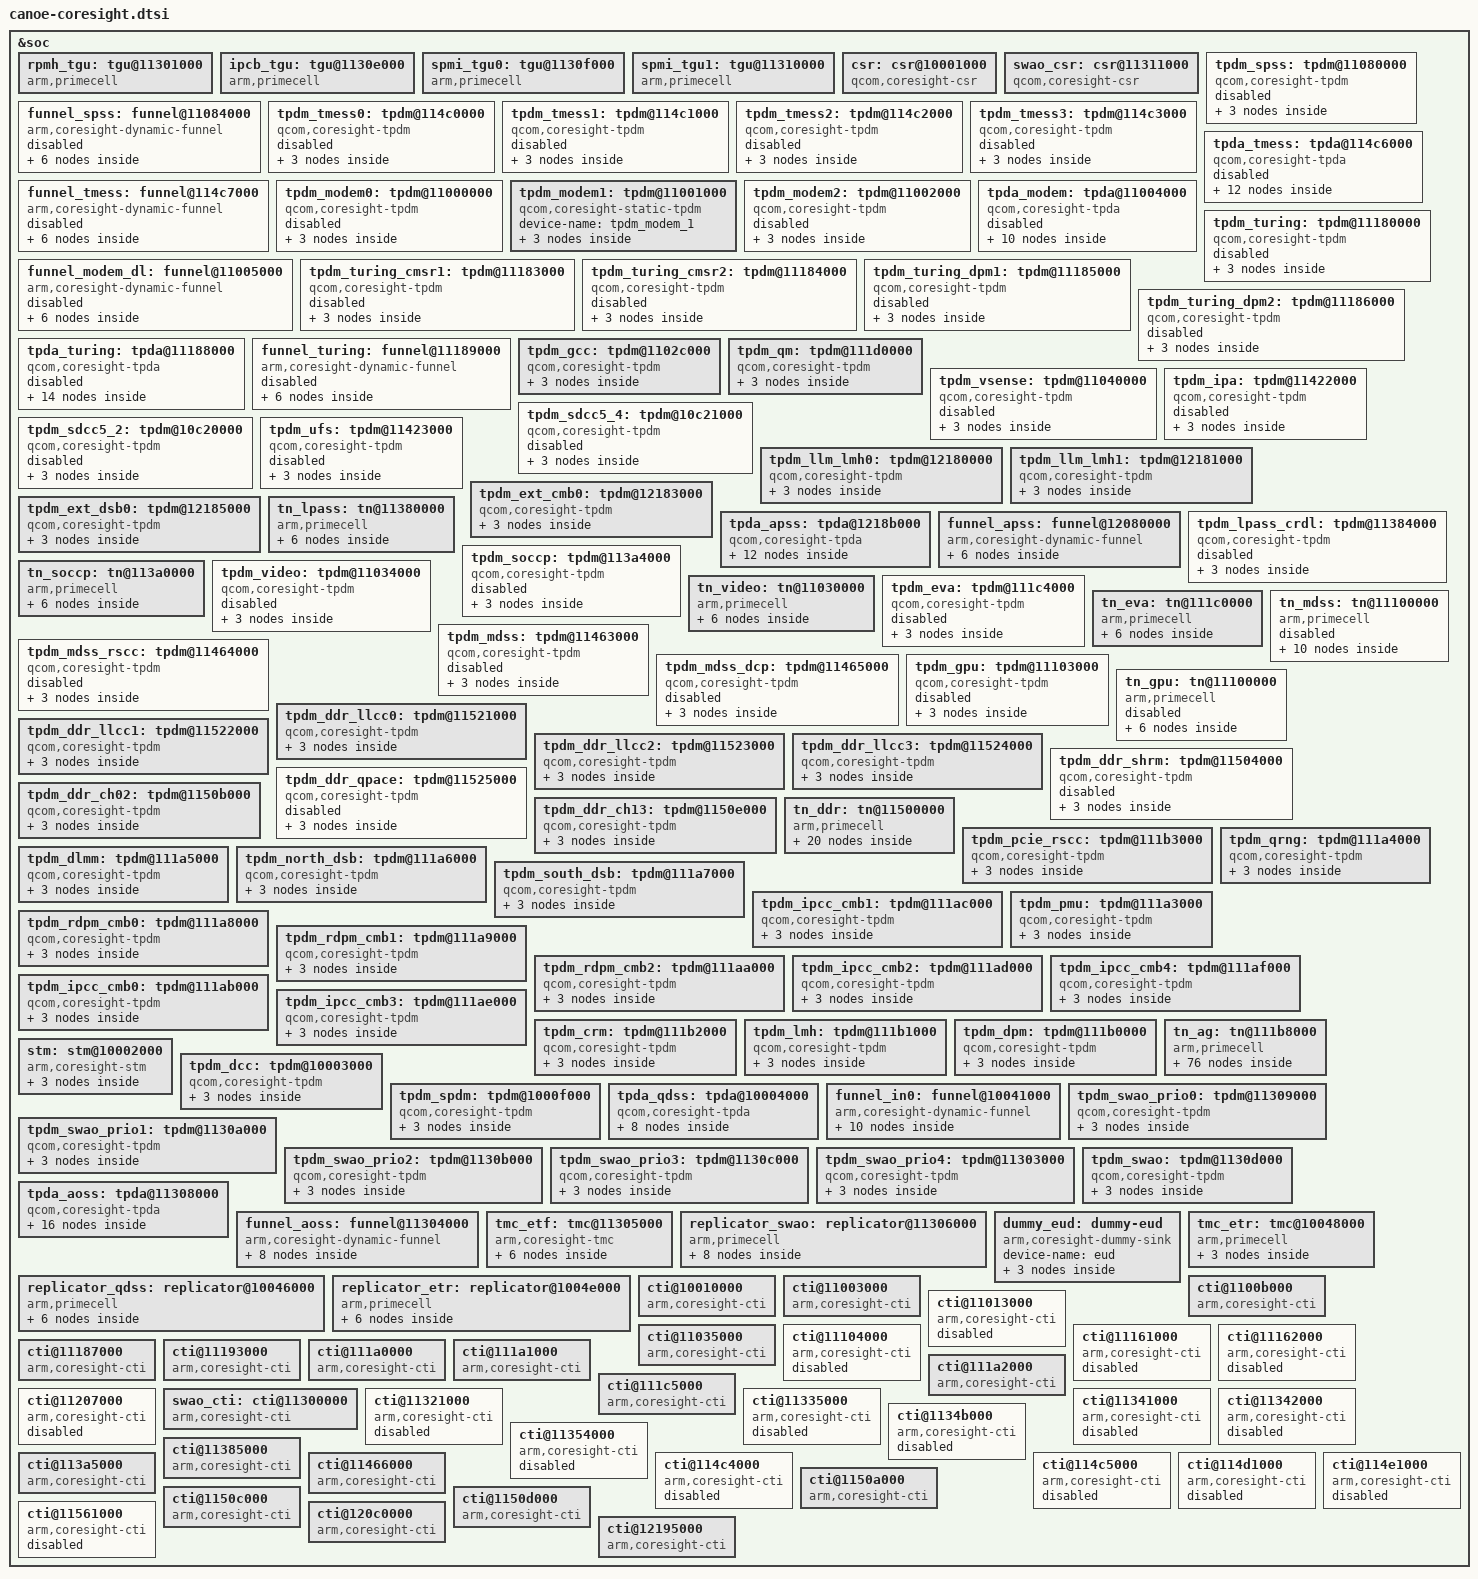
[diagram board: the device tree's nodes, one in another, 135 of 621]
// SPDX-License-Identifier: BSD-3-Clause
/*
 * Copyright (c) 2024 Qualcomm Innovation Center, Inc. All rights reserved.
 */

&soc {
	rpmh_tgu: tgu@11301000 {
		compatible = "arm,primecell";
		arm,primecell-periphid = <0x000bb999>;
		reg = <0x0 0x11301000 0x0 0x1000>;
		reg-names = "tgu-base";
		tgu-steps = <4>;
		tgu-conditions = <4>;
		tgu-regs = <16>;
		tgu-timer-counters = <8>;

		device-name = "tgu_rpmh";

		clocks = <&aoss_qmp>;
		clock-names = "apb_pclk";
	};

	ipcb_tgu: tgu@1130e000 {
		compatible = "arm,primecell";
		arm,primecell-periphid = <0x000bb999>;
		reg = <0x0 0x1130e000 0x0 0x1000>;
		reg-names = "tgu-base";
		tgu-steps = <3>;
		tgu-conditions = <4>;
		tgu-regs = <4>;
		tgu-timer-counters = <8>;

		device-name = "tgu_ipcb";

		clocks = <&aoss_qmp>;
		clock-names = "apb_pclk";
	};

	spmi_tgu0: tgu@1130f000 {
		compatible = "arm,primecell";
		arm,primecell-periphid = <0x000bb999>;

		reg = <0x0 0x1130f000 0x0 0x1000>;
		reg-names = "tgu-base";

		tgu-steps = <3>;
		tgu-conditions = <4>;
		tgu-regs = <9>;
		tgu-timer-counters = <8>;

		device-name = "tgu_spmi0";

		clocks = <&aoss_qmp>;
		clock-names = "apb_pclk";
	};

	spmi_tgu1: tgu@11310000 {
		compatible = "arm,primecell";
		arm,primecell-periphid = <0x000bb999>;

		reg = <0x0 0x11310000 0x0 0x1000>;
		reg-names = "tgu-base";

		tgu-steps = <3>;
		tgu-conditions = <4>;
		tgu-regs = <9>;
		tgu-timer-counters = <8>;

		device-name = "tgu_spmi1";

		clocks = <&aoss_qmp>;
		clock-names = "apb_pclk";
	};

	csr: csr@10001000 {
		compatible = "qcom,coresight-csr";
		reg = <0x0 0x10001000 0x0 0x1000>;
		reg-names = "csr-base";

		device-name = "csr";

		qcom,hwctrl-set-support;
		qcom,set-byte-cntr-support;
		qcom,blk-size = <1>;
	};

	swao_csr: csr@11311000 {
		compatible = "qcom,coresight-csr";
		reg = <0x0 0x11311000 0x0 0x1000>,
		      <0x0 0x113110f8 0x0 0x78>;
		reg-names = "csr-base", "msr-base";

		device-name = "swao_csr";

		qcom,timestamp-support;
		qcom,msr-support;
		qcom,blk-size = <1>;

		clocks = <&aoss_qmp>;
		clock-names = "apb_pclk";
	};

	tpdm_spss: tpdm@11080000 {
		compatible = "qcom,coresight-tpdm", "arm,primecell";
		reg = <0x0 0x11080000 0x0 0x1000>;
		reg-names = "tpdm-base";

		device-name = "tpdm_spss";

		clocks = <&aoss_qmp>;
		clock-names = "apb_pclk";
		status = "disabled";

		out-ports {
			port {
				tpdm_spss_out_funnel_spss: endpoint {
					remote-endpoint =
					<&funnel_spss_in_tpdm_spss>;
				};
			};
		};
	};

	funnel_spss: funnel@11084000 {
		compatible = "arm,coresight-dynamic-funnel", "arm,primecell";
		reg = <0x0 0x11084000 0x0 0x1000>;
		reg-names = "funnel-base";

		device-name = "coresight-funnel-spss";

		clocks = <&aoss_qmp>;
		clock-names = "apb_pclk";
		status = "disabled";

		in-ports {
			#address-cells = <1>;
			#size-cells = <0>;

			port@0 {
				reg = <0>;
				funnel_spss_in_tpdm_spss: endpoint {
					remote-endpoint =
					<&tpdm_spss_out_funnel_spss>;
				};
			};
		};

		out-ports {
			port {
				funnel_spss_out_tn_ag: endpoint {
					remote-endpoint =
					<&tn_ag_in_funnel_spss>;
				};
			};
		};
	};

	tpdm_tmess0: tpdm@114c0000 {
		compatible = "qcom,coresight-tpdm", "arm,primecell";
		reg = <0x0 0x114c0000 0x0 0x1000>;
		reg-names = "tpdm-base";
		qcom,cmb-element-bits = <32>;

		device-name = "tpdm_tmess_0";

		clocks = <&aoss_qmp>;
		clock-names = "apb_pclk";

		qcom,hw-enable-check;
		status = "disabled";

		out-ports {
			port {
				tpdm_tmess0_out_tpda_tmess: endpoint {
					remote-endpoint =
					<&tpda_tmess_in_tpdm_tmess0>;
				};
			};
		};
	};

	tpdm_tmess1: tpdm@114c1000 {
		compatible = "qcom,coresight-tpdm", "arm,primecell";
		reg = <0x0 0x114c1000 0x0 0x1000>;
		reg-names = "tpdm-base";
		qcom,cmb-element-bits = <32>;

		device-name = "tpdm_tmess_1";

		clocks = <&aoss_qmp>;
		clock-names = "apb_pclk";

		qcom,hw-enable-check;
		status = "disabled";

		out-ports {
			port {
				tpdm_tmess1_out_tpda_tmess: endpoint {
					remote-endpoint =
					<&tpda_tmess_in_tpdm_tmess1>;
				};
			};
		};
	};

	tpdm_tmess2: tpdm@114c2000 {
		compatible = "qcom,coresight-tpdm", "arm,primecell";
		reg = <0x0 0x114c2000 0x0 0x1000>;
		reg-names = "tpdm-base";
		qcom,cmb-element-bits = <32>;

		device-name = "tpdm_tmess_2";

		clocks = <&aoss_qmp>;
		clock-names = "apb_pclk";

		qcom,hw-enable-check;
		status = "disabled";

		out-ports {
			port {
				tpdm_tmess2_out_tpda_tmess: endpoint {
					remote-endpoint =
					<&tpda_tmess_in_tpdm_tmess2>;
				};
			};
		};
	};

	tpdm_tmess3: tpdm@114c3000 {
		compatible = "qcom,coresight-tpdm", "arm,primecell";
		reg = <0x0 0x114c3000 0x0 0x1000>;
		reg-names = "tpdm-base";
		qcom,dsb-element-bits = <32>;
		qcom,cmb-element-bits = <64>;

		device-name = "tpdm_tmess_3";

		clocks = <&aoss_qmp>;
		clock-names = "apb_pclk";

		qcom,hw-enable-check;
		status = "disabled";

		out-ports {
			port {
				tpdm_tmess3_out_tpda_tmess: endpoint {
					remote-endpoint =
					<&tpda_tmess_in_tpdm_tmess3>;
				};
			};
		};
	};

	tpda_tmess: tpda@114c6000 {
		compatible = "qcom,coresight-tpda", "arm,primecell";
		reg = <0x0 0x114c6000 0x0 0x1000>;
		reg-names = "tpda-base";

		device-name = "tpda_tmess";

		clocks = <&aoss_qmp>;
		clock-names = "apb_pclk";
		status = "disabled";

		in-ports {
			#address-cells = <1>;
			#size-cells = <0>;

			port@0 {
				reg = <0>;
				tpda_tmess_in_tpdm_tmess0: endpoint {
					remote-endpoint =
					<&tpdm_tmess0_out_tpda_tmess>;
				};
			};

			port@1 {
				reg = <1>;
				tpda_tmess_in_tpdm_tmess1: endpoint {
					remote-endpoint =
					<&tpdm_tmess1_out_tpda_tmess>;
				};
			};

			port@2 {
				reg = <2>;
				tpda_tmess_in_tpdm_tmess2: endpoint {
					remote-endpoint =
					<&tpdm_tmess2_out_tpda_tmess>;
				};
			};

			port@3 {
				reg = <3>;
				tpda_tmess_in_tpdm_tmess3: endpoint {
					remote-endpoint =
					<&tpdm_tmess3_out_tpda_tmess>;
				};
			};
		};

		out-ports {
			port {
				tpda_tmess_out_funnel_tmess: endpoint {
					remote-endpoint =
					<&funnel_tmess_in_tpda_tmess>;
				};
			};
		};
	};

	funnel_tmess: funnel@114c7000 {
		compatible = "arm,coresight-dynamic-funnel", "arm,primecell";
		reg = <0x0 0x114c7000 0x0 0x1000>;
		reg-names = "funnel-base";

		device-name = "funnel_tmess";

		clocks = <&aoss_qmp>;
		clock-names = "apb_pclk";
		status = "disabled";

		in-ports {
			#address-cells = <1>;
			#size-cells = <0>;

			port@0 {
				reg = <0>;
				funnel_tmess_in_tpda_tmess: endpoint {
					remote-endpoint =
					<&tpda_tmess_out_funnel_tmess>;
				};
			};
		};

		out-ports {
			#address-cells = <1>;
			#size-cells = <0>;

			port@0 {
				reg = <0>;
				funnel_tmess_out_tn_ag: endpoint {
					remote-endpoint =
					<&tn_ag_in_funnel_tmess>;
				};
			};
		};
	};

	tpdm_modem0: tpdm@11000000 {
		compatible = "qcom,coresight-tpdm", "arm,primecell";
		reg = <0x0 0x11000000 0x0 0x1000>;
		reg-names = "tpdm-base";
		qcom,dsb-element-bits = <32>;

		device-name = "tpdm_modem_0";

		clocks = <&aoss_qmp>;
		clock-names = "apb_pclk";
		status = "disabled";

		out-ports {
			port {
				tpdm_modem0_out_tpda_modem: endpoint {
					remote-endpoint =
					<&tpda_modem_in_tpdm_modem0>;
				};
			};
		};
	};

	tpdm_modem1: tpdm@11001000 {
		compatible = "qcom,coresight-static-tpdm";

		device-name = "tpdm_modem_1";

		out-ports {
			port {
				tpdm_modem1_out_tpda_modem: endpoint {
					remote-endpoint =
					<&tpda_modem_in_tpdm_modem1>;
				};
			};
		};
	};

	tpdm_modem2: tpdm@11002000 {
		compatible = "qcom,coresight-tpdm", "arm,primecell";
		reg = <0x0 0x11002000 0x0 0x1000>;
		reg-names = "tpdm-base";
		qcom,cmb-element-bits = <32>;

		device-name = "tpdm_modem_2";

		clocks = <&aoss_qmp>;
		clock-names = "apb_pclk";
		status = "disabled";

		out-ports {
			port {
				tpdm_modem2_out_tpda_modem: endpoint {
					remote-endpoint =
					<&tpda_modem_in_tpdm_modem2>;
				};
			};
		};
	};

	tpda_modem: tpda@11004000 {
		compatible = "qcom,coresight-tpda", "arm,primecell";
		reg = <0x0 0x11004000 0x0 0x1000>;
		reg-names = "tpda-base";

		device-name = "tpda_modem";

		clocks = <&aoss_qmp>;
		clock-names = "apb_pclk";
		status = "disabled";

		in-ports {
			#address-cells = <1>;
			#size-cells = <0>;

			port@0 {
				reg = <0>;
				tpda_modem_in_tpdm_modem0: endpoint {
					remote-endpoint =
					<&tpdm_modem0_out_tpda_modem>;
				};
			};

			port@1 {
				reg = <1>;
				tpda_modem_in_tpdm_modem1: endpoint {
					remote-endpoint =
					<&tpdm_modem1_out_tpda_modem>;
				};
			};

			port@2 {
				reg = <2>;
				tpda_modem_in_tpdm_modem2: endpoint {
					remote-endpoint =
					<&tpdm_modem2_out_tpda_modem>;
				};
			};
		};

		out-ports {
			port {
				tpda_modem_out_funnel_modem_dl: endpoint {
					remote-endpoint =
					<&funnel_modem_dl_in_tpda_modem>;
				};
			};
		};
	};

	funnel_modem_dl: funnel@11005000 {
		compatible = "arm,coresight-dynamic-funnel", "arm,primecell";
		reg = <0x0 0x11005000 0x0 0x1000>;
		reg-names = "funnel-base";

		device-name = "funnel_modem_dl";

		clocks = <&aoss_qmp>;
		clock-names = "apb_pclk";
		status = "disabled";

		in-ports {

			#address-cells = <1>;
			#size-cells = <0>;

			port@0 {
				reg = <0>;
				funnel_modem_dl_in_tpda_modem: endpoint {
					remote-endpoint =
					<&tpda_modem_out_funnel_modem_dl>;
				};
			};
		};

		out-ports {

			port {
				funnel_modem_dl_out_tn_ag: endpoint {
					remote-endpoint =
					<&tn_ag_in_funnel_modem_dl>;
				};
			};
		};
	};

	tpdm_turing: tpdm@11180000 {
		compatible = "qcom,coresight-tpdm", "arm,primecell";
		reg = <0x0 0x11180000 0x0 0x1000>;
		reg-names = "tpdm-base";
		qcom,dsb-element-bits = <32>;

		device-name = "tpdm_turing";

		clocks = <&aoss_qmp>;
		clock-names = "apb_pclk";
		status = "disabled";

		out-ports {
			port {
				tpdm_turing_out_tpda_turing: endpoint {
					remote-endpoint =
					<&tpda_turing_in_tpdm_turing>;
				};
			};
		};
	};

	tpdm_turing_cmsr1: tpdm@11183000 {
		compatible = "qcom,coresight-tpdm", "arm,primecell";
		reg = <0x0 0x11183000 0x0 0x1000>;
		reg-names = "tpdm-base";
		qcom,dsb-element-bits = <32>;
		qcom,cmb-element-bits = <32>;

		device-name = "tpdm_turing_cmsr1";

		clocks = <&aoss_qmp>;
		clock-names = "apb_pclk";
		status = "disabled";

		out-ports {
			port {
				tpdm_turing_cmsr1_out_tpda_turing: endpoint {
					remote-endpoint =
					<&tpda_turing_in_tpdm_turing_cmsr1>;
				};
			};
		};
	};

	tpdm_turing_cmsr2: tpdm@11184000 {
		compatible = "qcom,coresight-tpdm", "arm,primecell";
		reg = <0x0 0x11184000 0x0 0x1000>;
		reg-names = "tpdm-base";
		qcom,dsb-element-bits = <32>;
		qcom,cmb-element-bits = <32>;

		device-name = "tpdm_turing_cmsr2";

		clocks = <&aoss_qmp>;
		clock-names = "apb_pclk";
		status = "disabled";

		out-ports {
			port {
				tpdm_turing_cmsr2_out_tpda_turing: endpoint {
					remote-endpoint =
					<&tpda_turing_in_tpdm_turing_cmsr2>;
				};
			};
		};
	};

	tpdm_turing_dpm1: tpdm@11185000 {
		compatible = "qcom,coresight-tpdm", "arm,primecell";
		reg = <0x0 0x11185000 0x0 0x1000>;
		reg-names = "tpdm-base";
		qcom,cmb-element-bits = <64>;

		device-name = "tpdm_turing_dpm1";

		clocks = <&aoss_qmp>;
		clock-names = "apb_pclk";
		status = "disabled";

		out-ports {
			port {
				tpdm_turing_dpm1_out_tpda_turing: endpoint {
					remote-endpoint =
					<&tpda_turing_in_tpdm_turing_dpm1>;
				};
			};
		};
	};

	tpdm_turing_dpm2: tpdm@11186000 {
		compatible = "qcom,coresight-tpdm", "arm,primecell";
		reg = <0x0 0x11186000 0x0 0x1000>;
		reg-names = "tpdm-base";
		qcom,cmb-element-bits = <64>;

		device-name = "tpdm_turing_dpm2";

		clocks = <&aoss_qmp>;
		clock-names = "apb_pclk";
		status = "disabled";

		out-ports {
			port {
				tpdm_turing_dpm2_out_tpda_turing: endpoint {
					remote-endpoint =
					<&tpda_turing_in_tpdm_turing_dpm2>;
				};
			};
		};
	};

	tpda_turing: tpda@11188000 {
		compatible = "qcom,coresight-tpda", "arm,primecell";
		reg = <0x0 0x11188000 0x0 0x1000>;
		reg-names = "tpda-base";

		device-name = "tpda_turing";

		clocks = <&aoss_qmp>;
		clock-names = "apb_pclk";
		status = "disabled";

		in-ports {
			#address-cells = <1>;
			#size-cells = <0>;

			port@0 {
				reg = <0>;
				tpda_turing_in_tpdm_turing: endpoint {
					remote-endpoint =
					<&tpdm_turing_out_tpda_turing>;
				};
			};

			port@3 {
				reg = <3>;
				tpda_turing_in_tpdm_turing_cmsr1: endpoint {
					remote-endpoint =
					<&tpdm_turing_cmsr1_out_tpda_turing>;
				};
			};

			port@4 {
				reg = <4>;
				tpda_turing_in_tpdm_turing_cmsr2: endpoint {
					remote-endpoint =
					<&tpdm_turing_cmsr2_out_tpda_turing>;
				};
			};

			port@5 {
				reg = <5>;
				tpda_turing_in_tpdm_turing_dpm1: endpoint {
					remote-endpoint =
					<&tpdm_turing_dpm1_out_tpda_turing>;
				};
			};

			port@6 {
				reg = <6>;
				tpda_turing_in_tpdm_turing_dpm2: endpoint {
					remote-endpoint =
					<&tpdm_turing_dpm2_out_tpda_turing>;
				};
			};
		};

		out-ports {
			#address-cells = <1>;
			#size-cells = <0>;

			port@0 {
				reg = <0>;
				tpda_turing_out_funnel_turing: endpoint {
					remote-endpoint =
					<&funnel_turing_in_tpda_turing>;
				};
			};
		};
	};

	funnel_turing: funnel@11189000 {
		compatible = "arm,coresight-dynamic-funnel", "arm,primecell";
		reg = <0x0 0x11189000 0x0 0x1000>;
		reg-names = "funnel-base";

		device-name = "funnel_turing";

		clocks = <&aoss_qmp>;
		clock-names = "apb_pclk";
		status = "disabled";

		in-ports {
			#address-cells = <1>;
			#size-cells = <0>;

			port@0 {
				reg = <0>;
				funnel_turing_in_tpda_turing: endpoint {
					remote-endpoint =
					<&tpda_turing_out_funnel_turing>;
				};
			};
		};

		out-ports {
			#address-cells = <1>;
			#size-cells = <0>;

			port@0 {
				reg = <0>;
				funnel_turing_out_tn_ag: endpoint {
					remote-endpoint =
					<&tn_ag_in_funnel_turing>;
				};
			};
		};
	};

	tpdm_gcc: tpdm@1102c000 {
		compatible = "qcom,coresight-tpdm", "arm,primecell";
		reg = <0x0 0x1102c000 0x0 0x1000>;
		reg-names = "tpdm-base";

		device-name = "tpdm_gcc";

		clocks = <&aoss_qmp>;
		clock-names = "apb_pclk";

		out-ports {
			port {
				tpdm_gcc_out_tn_ag: endpoint {
					remote-endpoint =
					<&tn_ag_in_tpdm_gcc>;
				};
			};
		};
	};

	tpdm_qm: tpdm@111d0000 {
		compatible = "qcom,coresight-tpdm", "arm,primecell";
		reg = <0x0 0x111d0000 0x0 0x1000>;
		reg-names = "tpdm-base";

		device-name = "tpdm_qm";

		clocks = <&aoss_qmp>;
		clock-names = "apb_pclk";

		out-ports {
			port {
				tpdm_qm_out_tn_ag: endpoint {
					remote-endpoint =
					<&tn_ag_in_tpdm_qm>;
				};
			};
		};
	};

	tpdm_vsense: tpdm@11040000 {
		compatible = "qcom,coresight-tpdm", "arm,primecell";
		reg = <0x0 0x11040000 0x0 0x1000>;
		reg-names = "tpdm-base";

		device-name = "tpdm_vsense";
		status = "disabled";

		clocks = <&aoss_qmp>;
		clock-names = "apb_pclk";

		out-ports {
			port {
				tpdm_vsense_out_tn_ag: endpoint {
					remote-endpoint =
					<&tn_ag_in_tpdm_vsense>;
				};
			};
		};
	};

	tpdm_ipa: tpdm@11422000 {
		compatible = "qcom,coresight-tpdm", "arm,primecell";
		reg = <0x0 0x11422000 0x0 0x1000>;
		reg-names = "tpdm-base";

		device-name = "tpdm_ipa";

		clocks = <&aoss_qmp>;
		clock-names = "apb_pclk";
		status = "disabled";

		out-ports {
			port {
				tpdm_ipa_out_tn_ag: endpoint {
					remote-endpoint =
					<&tn_ag_in_tpdm_ipa>;
				};
			};
		};
	};

	tpdm_sdcc5_4: tpdm@10c21000 {
		compatible = "qcom,coresight-tpdm", "arm,primecell";
		reg = <0x0 0x10c21000 0x0 0x1000>;
		reg-names = "tpdm-base";

		device-name = "tpdm_sdcc4";

		clocks = <&aoss_qmp>;
		clock-names = "apb_pclk";
		status = "disabled";

		out-ports {
			port {
				tpdm_sdcc5_4_out_tn_ag: endpoint {
					remote-endpoint =
					<&tn_ag_in_tpdm_sdcc5_4>;
				};
			};
		};
	};

	tpdm_sdcc5_2: tpdm@10c20000 {
		compatible = "qcom,coresight-tpdm", "arm,primecell";
		reg = <0x0 0x10c20000 0x0 0x1000>;
		reg-names = "tpdm-base";

		device-name = "tpdm_sdcc2";

		clocks = <&aoss_qmp>;
		clock-names = "apb_pclk";
		status = "disabled";

		out-ports {
			port {
				tpdm_sdcc5_2_out_tn_ag: endpoint {
					remote-endpoint =
					<&tn_ag_in_tpdm_sdcc5_2>;
				};
			};
		};
	};

	tpdm_ufs: tpdm@11423000 {
		compatible = "qcom,coresight-tpdm", "arm,primecell";
		reg = <0x0 0x11423280 0x0 0x1000>;
		reg-names = "tpdm-base";

		device-name = "tpdm_ufs";

		clocks = <&aoss_qmp>;
		clock-names = "apb_pclk";
		status = "disabled";

		out-ports {
			port {
				tpdm_ufs_out_tn_ag: endpoint {
					remote-endpoint =
					<&tn_ag_in_tpdm_ufs>;
				};
			};
		};
	};

	tpdm_llm_lmh0: tpdm@12180000 {
		compatible = "qcom,coresight-tpdm", "arm,primecell";
		reg = <0x0 0x12180000 0x0 0x1000>;
		reg-names = "tpdm-base";
		qcom,cmb-element-bits = <32>;

		device-name = "tpdm_llm_lmh0";

		clocks = <&aoss_qmp>,
			<&rpmhcc RPMH_CXO_CLK>;
		clock-names = "apb_pclk",
				"dynamic_clk";

		out-ports {
			port {
				tpdm_llm_lmh0_out_tpda_apss: endpoint {
					remote-endpoint =
					<&tpda_apss_in_tpdm_llm_lmh0>;
				};
			};
		};
	};

	tpdm_llm_lmh1: tpdm@12181000 {
		compatible = "qcom,coresight-tpdm", "arm,primecell";
		reg = <0x0 0x12181000 0x0 0x1000>;
		reg-names = "tpdm-base";
		qcom,cmb-element-bits = <32>;

		device-name = "tpdm_llm_lmh1";

		clocks = <&aoss_qmp>,
			<&rpmhcc RPMH_CXO_CLK>;
		clock-names = "apb_pclk",
				"dynamic_clk";

		out-ports {
			port {
				tpdm_llm_lmh1_out_tpda_apss: endpoint {
					remote-endpoint =
					<&tpda_apss_in_tpdm_llm_lmh1>;
				};
			};
		};
	};

	tpdm_ext_cmb0: tpdm@12183000 {
		compatible = "qcom,coresight-tpdm", "arm,primecell";
		reg = <0x0 0x12183000 0x0 0x1000>;
		reg-names = "tpdm-base";
		qcom,cmb-element-bits = <64>;

		device-name = "tpdm_ext_cmb0";

		clocks = <&aoss_qmp>,
			<&rpmhcc RPMH_CXO_CLK>;
		clock-names = "apb_pclk",
				"dynamic_clk";

		out-ports {
			port {
				tpdm_ext_cmb0_out_tpda_apss: endpoint {
					remote-endpoint =
					<&tpda_apss_in_tpdm_ext_cmb0>;
				};
			};
		};
	};

	tpdm_ext_dsb0: tpdm@12185000 {
		compatible = "qcom,coresight-tpdm", "arm,primecell";
		reg = <0x0 0x12185000 0x0 0x1000>;
		reg-names = "tpdm-base";
		qcom,dsb-element-bits = <32>;

		device-name = "tpdm_ext_dsb0";

		clocks = <&aoss_qmp>,
			<&rpmhcc RPMH_CXO_CLK>;
		clock-names = "apb_pclk",
				"dynamic_clk";

		out-ports {
			port {
				tpdm_ext_dsb0_out_tpda_apss: endpoint {
					remote-endpoint =
					<&tpda_apss_in_tpdm_ext_dsb0>;
				};
			};
		};
	};

	tpda_apss: tpda@1218b000 {
		compatible = "qcom,coresight-tpda", "arm,primecell";
		reg = <0x0 0x1218b000 0x0 0x1000>;
		reg-names = "tpda-base";

		device-name = "tpda_apss";

		clocks = <&aoss_qmp>,
			<&rpmhcc RPMH_CXO_CLK>;
		clock-names = "apb_pclk",
				"dynamic_clk";

		in-ports {
			#address-cells = <1>;
			#size-cells = <0>;

			port@0 {
				reg = <0>;
				tpda_apss_in_tpdm_llm_lmh0: endpoint {
					remote-endpoint =
					<&tpdm_llm_lmh0_out_tpda_apss>;
				};
			};

			port@1 {
				reg = <1>;
				tpda_apss_in_tpdm_llm_lmh1: endpoint {
					remote-endpoint =
					<&tpdm_llm_lmh1_out_tpda_apss>;
				};
			};

			port@3 {
				reg = <3>;
				tpda_apss_in_tpdm_ext_cmb0: endpoint {
					remote-endpoint =
					<&tpdm_ext_cmb0_out_tpda_apss>;
				};
			};

			port@4 {
				reg = <4>;
				tpda_apss_in_tpdm_ext_dsb0: endpoint {
					remote-endpoint =
					<&tpdm_ext_dsb0_out_tpda_apss>;
				};
			};
		};

		out-ports {
			port {
				tpda_apss_out_funnel_apss: endpoint {
					remote-endpoint =
					<&funnel_apss_in_tpda_apss>;
				};
			};
		};
	};

	funnel_apss: funnel@12080000 {
		compatible = "arm,coresight-dynamic-funnel", "arm,primecell";
		reg = <0x0 0x12080000 0x0 0x1000>;
		reg-names = "funnel-base";

		device-name = "funnel_apss";

		clocks = <&aoss_qmp>,
			<&rpmhcc RPMH_CXO_CLK>;
		clock-names = "apb_pclk",
				"dynamic_clk";


		in-ports {
			#address-cells = <1>;
			#size-cells = <0>;

			port@5 {
				reg = <5>;
				funnel_apss_in_tpda_apss: endpoint {
					remote-endpoint =
					<&tpda_apss_out_funnel_apss>;
				};
			};
		};

		out-ports {
			port {
				funnel_apss_out_tn_ag: endpoint {
					remote-endpoint =
					<&tn_ag_in_funnel_apss>;
				};
			};
		};
	};

	tpdm_lpass_crdl: tpdm@11384000 {
		compatible = "qcom,coresight-tpdm", "arm,primecell";
		reg = <0x0 0x11384000 0x0 0x1000>;
		reg-names = "tpdm-base";

		device-name = "tpdm_lpass_crdl";

		clocks = <&aoss_qmp>;
		clock-names = "apb_pclk";
		status = "disabled";

		out-ports {
			port {
				tpdm_crdl_out_tn_lpass: endpoint {
					remote-endpoint =
					<&tn_lpass_in_tpdm_crdl>;
				};
			};
		};
	};

	tn_lpass: tn@11380000 {
		compatible = "arm,primecell";
		arm,primecell-periphid = <0x000f0c00>;
		reg = <0x0 0x11380000 0x0 0x1000>;
		reg-names = "traceNoc-base";

		device-name = "tracenoc_lpass";

		clocks = <&aoss_qmp>;
		clock-names = "apb_pclk";

		in-ports {
			#address-cells = <1>;
			#size-cells = <0>;

			port@0 {
				reg = <0>;
				tn_lpass_in_tpdm_crdl: endpoint {
					remote-endpoint =
					<&tpdm_crdl_out_tn_lpass>;
				};
			};
		};

		out-ports {
			port {
				tn_lpass_out_tn_ag: endpoint {
					remote-endpoint =
					<&tn_ag_in_tn_lpass>;
				};
			};
		};
	};

	tpdm_soccp: tpdm@113a4000 {
		compatible = "qcom,coresight-tpdm", "arm,primecell";
		reg = <0x0 0x113a4000 0x0 0x1000>;
		reg-names = "tpdm-base";

		device-name = "tpdm_soccp";

		clocks = <&aoss_qmp>;
		clock-names = "apb_pclk";
		status = "disabled";

		out-ports {
			port {
				tpdm_soccp_out_tn_soccp: endpoint {
					remote-endpoint =
					<&tn_soccp_in_tpdm_soccp>;
				};
			};
		};
	};

	tn_soccp: tn@113a0000 {
		compatible = "arm,primecell";
		arm,primecell-periphid = <0x000f0c00>;
		reg = <0x0 0x113a0000 0x0 0x1000>;
		reg-names = "traceNoc-base";

		device-name = "tracenoc_soccp";

		clocks = <&aoss_qmp>;
		clock-names = "apb_pclk";

		in-ports {
			#address-cells = <1>;
			#size-cells = <0>;

			port@0 {
				reg = <0>;
				tn_soccp_in_tpdm_soccp: endpoint {
					remote-endpoint =
					<&tpdm_soccp_out_tn_soccp>;
				};
			};
		};

		out-ports {
			port {
				tn_soccp_out_tn_ag: endpoint {
					remote-endpoint =
					<&tn_ag_in_tn_soccp>;
				};
			};
		};
	};

	tpdm_video: tpdm@11034000 {
		compatible = "qcom,coresight-tpdm", "arm,primecell";
		reg = <0x0 0x11034000 0x0 0x1000>;
		reg-names = "tpdm-base";

		device-name = "tpdm_video";

		clocks = <&aoss_qmp>;
		clock-names = "apb_pclk";
		status = "disabled";

		out-ports {
			port {
				tpdm_video_out_tn_video: endpoint {
					remote-endpoint =
					<&tn_video_in_tpdm_video>;
				};
			};
		};
	};

	tn_video: tn@11030000 {
		compatible = "arm,primecell";
		arm,primecell-periphid = <0x000f0c00>;
		reg = <0x0 0x11030000 0x0 0x1000>;
		reg-names = "traceNoc-base";

		device-name = "tracenoc_video";

		clocks = <&aoss_qmp>;
		clock-names = "apb_pclk";

		in-ports {
			#address-cells = <1>;
			#size-cells = <0>;

			port@0 {
				reg = <0>;
				tn_video_in_tpdm_video: endpoint {
					remote-endpoint =
					<&tpdm_video_out_tn_video>;
				};
			};
		};

		out-ports {
			port {
				tn_video_out_tn_ag: endpoint {
					remote-endpoint =
					<&tn_ag_in_tn_video>;
				};
			};
		};
	};

	tpdm_eva: tpdm@111c4000 {
		compatible = "qcom,coresight-tpdm", "arm,primecell";
		reg = <0x0 0x111c4000 0x0 0x1000>;
		reg-names = "tpdm-base";

		device-name = "tpdm_eva";

		clocks = <&aoss_qmp>;
		clock-names = "apb_pclk";
		status = "disabled";

		out-ports {
			port {
				tpdm_eva_out_tn_eva: endpoint {
					remote-endpoint =
					<&tn_eva_in_tpdm_eva>;
				};
			};
		};
	};

	tn_eva: tn@111c0000 {
		compatible = "arm,primecell";
		arm,primecell-periphid = <0x000f0c00>;
		reg = <0x0 0x111c0000 0x0 0x1000>;
		reg-names = "traceNoc-base";

		device-name = "tracenoc_eva";

		clocks = <&aoss_qmp>;
		clock-names = "apb_pclk";

		in-ports {
			#address-cells = <1>;
			#size-cells = <0>;

			port@0 {
				reg = <0>;
				tn_eva_in_tpdm_eva: endpoint {
					remote-endpoint =
					<&tpdm_eva_out_tn_eva>;
				};
			};
		};

		out-ports {
			port {
				tn_eva_out_tn_ag: endpoint {
					remote-endpoint =
					<&tn_ag_in_tn_eva>;
				};
			};
		};
	};

	tpdm_mdss: tpdm@11463000 {
		compatible = "qcom,coresight-tpdm", "arm,primecell";
		reg = <0x0 0x11463000 0x0 0x1000>;
		reg-names = "tpdm-base";

		device-name = "tpdm_mdss";

		clocks = <&aoss_qmp>;
		clock-names = "apb_pclk";
		status = "disabled";

		out-ports {
			port {
				tpdm_mdss_out_tn_mdss: endpoint {
					remote-endpoint =
					<&tn_mdss_in_tpdm_mdss>;
				};
			};
		};
	};

	tpdm_mdss_rscc: tpdm@11464000 {
		compatible = "qcom,coresight-tpdm", "arm,primecell";
		reg = <0x0 0x11464000 0x0 0x1000>;
		reg-names = "tpdm-base";

		device-name = "tpdm_mdss_rscc";

		clocks = <&aoss_qmp>;
		clock-names = "apb_pclk";
		status = "disabled";

		out-ports {
			port {
				tpdm_mdss_rscc_out_tn_mdss: endpoint {
					remote-endpoint =
					<&tn_mdss_in_tpdm_mdss_rscc>;
				};
			};
		};
	};

	tpdm_mdss_dcp: tpdm@11465000 {
		compatible = "qcom,coresight-tpdm", "arm,primecell";
		reg = <0x0 0x11465000 0x0 0x1000>;
		reg-names = "tpdm-base";

		device-name = "tpdm_mdss_dcp";

		clocks = <&aoss_qmp>;
		clock-names = "apb_pclk";
		status = "disabled";

		out-ports {
			port {
				tpdm_mdss_dcp_out_tn_mdss: endpoint {
					remote-endpoint =
					<&tn_mdss_in_tpdm_mdss_dcp>;
				};
			};
		};
	};

	tn_mdss: tn@11100000 {
		compatible = "arm,primecell";
		arm,primecell-periphid = <0x000f0c00>;
		reg = <0x0 0x11100000 0x0 0x1000>;
		reg-names = "traceNoc-base";

		device-name = "tracenoc_mdss";

		clocks = <&aoss_qmp>;
		clock-names = "apb_pclk";
		status = "disabled";

		in-ports {
			#address-cells = <1>;
			#size-cells = <0>;

			port@0 {
				reg = <0>;
				tn_mdss_in_tpdm_mdss: endpoint {
					remote-endpoint =
					<&tpdm_mdss_out_tn_mdss>;
				};
			};

			port@1 {
				reg = <1>;
				tn_mdss_in_tpdm_mdss_rscc: endpoint {
					remote-endpoint =
					<&tpdm_mdss_rscc_out_tn_mdss>;
				};
			};

			port@2 {
				reg = <2>;
				tn_mdss_in_tpdm_mdss_dcp: endpoint {
					remote-endpoint =
					<&tpdm_mdss_dcp_out_tn_mdss>;
				};
			};
		};

		out-ports {
			port {
				tn_mdss_out_tn_ag: endpoint {
					remote-endpoint =
					<&tn_ag_in_tn_mdss>;
				};
			};
		};
	};

	tpdm_gpu: tpdm@11103000 {
		compatible = "qcom,coresight-tpdm", "arm,primecell";
		reg = <0x0 0x11103000 0x0 0x1000>;
		reg-names = "tpdm-base";

		device-name = "tpdm_gpu";

		clocks = <&aoss_qmp>;
		clock-names = "apb_pclk";
		status = "disabled";

		out-ports {
			port {
				tpdm_gpu_out_tn_gpu: endpoint {
					remote-endpoint =
					<&tn_gpu_in_tpdm_gpu>;
				};
			};
		};
	};

	tn_gpu: tn@11100000 {
		compatible = "arm,primecell";
		arm,primecell-periphid = <0x000f0c00>;
		reg = <0x0 0x11100000 0x0 0x1000>;
		reg-names = "traceNoc-base";

		device-name = "tracenoc_gpu";

		clocks = <&aoss_qmp>;
		clock-names = "apb_pclk";
		status = "disabled";

		in-ports {
			#address-cells = <1>;
			#size-cells = <0>;

			port@0 {
				reg = <0>;
				tn_gpu_in_tpdm_gpu: endpoint {
					remote-endpoint =
					<&tpdm_gpu_out_tn_gpu>;
				};
			};
		};

		out-ports {
			port {
				tn_gpu_out_tn_ag: endpoint {
					remote-endpoint =
					<&tn_ag_in_tn_gpu>;
				};
			};
		};
	};

	tpdm_ddr_llcc0: tpdm@11521000 {
		compatible = "qcom,coresight-tpdm", "arm,primecell";
		reg = <0x0 0x11521000 0x0 0x1000>;
		reg-names = "tpdm-base";

		device-name = "tpdm_ddr_llcc0";

		clocks = <&aoss_qmp>;
		clock-names = "apb_pclk";

		out-ports {
			port {
				tpdm_ddr_llcc0_out_tn_ddr: endpoint {
					remote-endpoint =
					<&tn_ddr_in_tpdm_ddr_llcc0>;
				};
			};
		};
	};

	tpdm_ddr_llcc1: tpdm@11522000 {
		compatible = "qcom,coresight-tpdm", "arm,primecell";
		reg = <0x0 0x11522000 0x0 0x1000>;
		reg-names = "tpdm-base";

		device-name = "tpdm_ddr_llcc1";

		clocks = <&aoss_qmp>;
		clock-names = "apb_pclk";

		out-ports {
			port {
				tpdm_ddr_llcc1_out_tn_ddr: endpoint {
					remote-endpoint =
					<&tn_ddr_in_tpdm_ddr_llcc1>;
				};
			};
		};
	};

	tpdm_ddr_llcc2: tpdm@11523000 {
		compatible = "qcom,coresight-tpdm", "arm,primecell";
		reg = <0x0 0x11523000 0x0 0x1000>;
		reg-names = "tpdm-base";

		device-name = "tpdm_ddr_llcc2";

		clocks = <&aoss_qmp>;
		clock-names = "apb_pclk";

		out-ports {
			port {
				tpdm_ddr_llcc2_out_tn_ddr: endpoint {
					remote-endpoint =
					<&tn_ddr_in_tpdm_ddr_llcc2>;
				};
			};
		};
	};

	tpdm_ddr_llcc3: tpdm@11524000 {
		compatible = "qcom,coresight-tpdm", "arm,primecell";
		reg = <0x0 0x11524000 0x0 0x1000>;
		reg-names = "tpdm-base";

		device-name = "tpdm_ddr_llcc3";

		clocks = <&aoss_qmp>;
		clock-names = "apb_pclk";

		out-ports {
			port {
				tpdm_ddr_llcc3_out_tn_ddr: endpoint {
					remote-endpoint =
					<&tn_ddr_in_tpdm_ddr_llcc3>;
				};
			};
		};
	};

	tpdm_ddr_shrm: tpdm@11504000 {
		compatible = "qcom,coresight-tpdm", "arm,primecell";
		reg = <0x0 0x11504000 0x0 0x1000>;
		reg-names = "tpdm-base";

		device-name = "tpdm_ddr_shrm";

		clocks = <&aoss_qmp>;
		clock-names = "apb_pclk";
		status = "disabled";

		out-ports {
			port {
				tpdm_ddr_shrm_out_tn_ddr: endpoint {
					remote-endpoint =
					<&tn_ddr_in_tpdm_ddr_shrm>;
				};
			};
		};
	};

	tpdm_ddr_qpace: tpdm@11525000 {
		compatible = "qcom,coresight-tpdm", "arm,primecell";
		reg = <0x0 0x11525000 0x0 0x1000>;
		reg-names = "tpdm-base";

		device-name = "tpdm_ddr_qpace";

		clocks = <&aoss_qmp>;
		clock-names = "apb_pclk";
		status = "disabled";

		out-ports {
			port {
				tpdm_ddr_qpace_out_tn_ddr: endpoint {
					remote-endpoint =
					<&tn_ddr_in_tpdm_ddr_qpace>;
				};
			};
		};
	};

	tpdm_ddr_ch02: tpdm@1150b000 {
		compatible = "qcom,coresight-tpdm", "arm,primecell";
		reg = <0x0 0x1150b000 0x0 0x1000>;
		reg-names = "tpdm-base";

		device-name = "tpdm_ddr_ch02";

		clocks = <&aoss_qmp>;
		clock-names = "apb_pclk";

		out-ports {
			port {
				tpdm_ddr_ch02_out_tn_ddr: endpoint {
					remote-endpoint =
					<&tn_ddr_in_tpdm_ddr_ch02>;
				};
			};
		};
	};

	tpdm_ddr_ch13: tpdm@1150e000 {
		compatible = "qcom,coresight-tpdm", "arm,primecell";
		reg = <0x0 0x1150e000 0x0 0x1000>;
		reg-names = "tpdm-base";

		device-name = "tpdm_ddr_ch13";

		clocks = <&aoss_qmp>;
		clock-names = "apb_pclk";

		out-ports {
			port {
				tpdm_ddr_ch13_out_tn_ddr: endpoint {
					remote-endpoint =
					<&tn_ddr_in_tpdm_ddr_ch13>;
				};
			};
		};
	};

	tn_ddr: tn@11500000 {
		compatible = "arm,primecell";
		arm,primecell-periphid = <0x000f0c00>;
		reg = <0x0 0x11500000 0x0 0x3c00>;
		reg-names = "traceNoc-base";

		device-name = "tracenoc_ddr";

		clocks = <&aoss_qmp>;
		clock-names = "apb_pclk";

		in-ports {
			#address-cells = <1>;
			#size-cells = <0>;

			port@7 {
				reg = <7>;
				tn_ddr_in_tpdm_ddr_llcc0: endpoint {
					remote-endpoint =
					<&tpdm_ddr_llcc0_out_tn_ddr>;
				};
			};

			port@8 {
				reg = <8>;
				tn_ddr_in_tpdm_ddr_llcc1: endpoint {
					remote-endpoint =
					<&tpdm_ddr_llcc1_out_tn_ddr>;
				};
			};

			port@9 {
				reg = <9>;
				tn_ddr_in_tpdm_ddr_llcc2: endpoint {
					remote-endpoint =
					<&tpdm_ddr_llcc2_out_tn_ddr>;
				};
			};

			port@a {
				reg = <10>;
				tn_ddr_in_tpdm_ddr_llcc3: endpoint {
					remote-endpoint =
					<&tpdm_ddr_llcc3_out_tn_ddr>;
				};
			};

			port@b {
				reg = <11>;
				tn_ddr_in_tpdm_ddr_shrm: endpoint {
					remote-endpoint =
					<&tpdm_ddr_shrm_out_tn_ddr>;
				};
			};

			port@c {
				reg = <12>;
				tn_ddr_in_tpdm_ddr_qpace: endpoint {
					remote-endpoint =
					<&tpdm_ddr_qpace_out_tn_ddr>;
				};
			};

			port@f {
				reg = <15>;
				tn_ddr_in_tpdm_ddr_ch02: endpoint {
					remote-endpoint =
					<&tpdm_ddr_ch02_out_tn_ddr>;
				};
			};

			port@10 {
				reg = <16>;
				tn_ddr_in_tpdm_ddr_ch13: endpoint {
					remote-endpoint =
					<&tpdm_ddr_ch13_out_tn_ddr>;
				};
			};
		};

		out-ports {
			port {
				tn_ddr_out_tn_ag: endpoint {
					remote-endpoint =
					<&tn_ag_in_tn_ddr>;
				};
			};
		};
	};

	tpdm_pcie_rscc: tpdm@111b3000 {
		compatible = "qcom,coresight-tpdm", "arm,primecell";
		reg = <0x0 0x111b3000 0x0 0x1000>;
		reg-names = "tpdm-base";

		device-name = "tpdm_pcie_rscc";

		clocks = <&aoss_qmp>;
		clock-names = "apb_pclk";

		out-ports {
			port {
				tpdm_pcie_rscc_out_tn_ag: endpoint {
					remote-endpoint =
					<&tn_ag_in_tpdm_pcie_rscc>;
				};
			};
		};
	};

	tpdm_qrng: tpdm@111a4000 {
		compatible = "qcom,coresight-tpdm", "arm,primecell";
		reg = <0x0 0x111a4000 0x0 0x1000>;
		reg-names = "tpdm-base";

		device-name = "tpdm_qrng";

		clocks = <&aoss_qmp>;
		clock-names = "apb_pclk";

		out-ports {
			port {
				tpdm_qrng_out_tn_ag: endpoint {
					remote-endpoint =
					<&tn_ag_in_tpdm_qrng>;
				};
			};
		};
	};

	tpdm_dlmm: tpdm@111a5000 {
		compatible = "qcom,coresight-tpdm", "arm,primecell";
		reg = <0x0 0x111a5000 0x0 0x1000>;
		reg-names = "tpdm-base";

		device-name = "tpdm_dlmm";

		clocks = <&aoss_qmp>;
		clock-names = "apb_pclk";

		out-ports {
			port {
				tpdm_dlmm_out_tn_ag: endpoint {
					remote-endpoint =
					<&tn_ag_in_tpdm_dlmm>;
				};
			};
		};
	};

	tpdm_north_dsb: tpdm@111a6000 {
		compatible = "qcom,coresight-tpdm", "arm,primecell";
		reg = <0x0 0x111a6000 0x0 0x1000>;
		reg-names = "tpdm-base";

		device-name = "tpdm_north_dsb";

		clocks = <&aoss_qmp>;
		clock-names = "apb_pclk";

		out-ports {
			port {
				tpdm_north_dsb_out_tn_ag: endpoint {
					remote-endpoint =
					<&tn_ag_in_tpdm_north_dsb>;
				};
			};
		};
	};

	tpdm_south_dsb: tpdm@111a7000 {
		compatible = "qcom,coresight-tpdm", "arm,primecell";
		reg = <0x0 0x111a7000 0x0 0x1000>;
		reg-names = "tpdm-base";

		device-name = "tpdm_south_dsb";

		clocks = <&aoss_qmp>;
		clock-names = "apb_pclk";

		out-ports {
			port {
				tpdm_south_dsb_out_tn_ag: endpoint {
					remote-endpoint =
					<&tn_ag_in_tpdm_south_dsb>;
				};
			};
		};
	};

	tpdm_ipcc_cmb1: tpdm@111ac000 {
		compatible = "qcom,coresight-tpdm", "arm,primecell";
		reg = <0x0 0x111ac000 0x0 0x1000>;
		reg-names = "tpdm-base";

		device-name = "tpdm_ipcc_cmb1";

		clocks = <&aoss_qmp>;
		clock-names = "apb_pclk";

		out-ports {
			port {
				tpdm_ipcc_cmb1_out_tn_ag: endpoint {
					remote-endpoint =
					<&tn_ag_in_tpdm_ipcc_cmb1>;
				};
			};
		};
	};

	tpdm_pmu: tpdm@111a3000 {
		compatible = "qcom,coresight-tpdm", "arm,primecell";
		reg = <0x0 0x111a3000 0x0 0x1000>;
		reg-names = "tpdm-base";

		device-name = "tpdm_pmu";

		clocks = <&aoss_qmp>;
		clock-names = "apb_pclk";

		out-ports {
			port {
				tpdm_pmu_out_tn_ag: endpoint {
					remote-endpoint =
					<&tn_ag_in_tpdm_pmu>;
				};
			};
		};
	};

	tpdm_rdpm_cmb0: tpdm@111a8000 {
		compatible = "qcom,coresight-tpdm", "arm,primecell";
		reg = <0x0 0x111a8000 0x0 0x1000>;
		reg-names = "tpdm-base";

		device-name = "tpdm_rdpm_cmb0";

		clocks = <&aoss_qmp>;
		clock-names = "apb_pclk";

		out-ports {
			port {
				tpdm_rdpm_cmb0_out_tn_ag: endpoint {
					remote-endpoint =
					<&tn_ag_in_tpdm_rdpm_cmb0>;
				};
			};
		};
	};

	tpdm_rdpm_cmb1: tpdm@111a9000 {
		compatible = "qcom,coresight-tpdm", "arm,primecell";
		reg = <0x0 0x111a9000 0x0 0x1000>;
		reg-names = "tpdm-base";

		device-name = "tpdm_rdpm_cmb1";

		clocks = <&aoss_qmp>;
		clock-names = "apb_pclk";

		out-ports {
			port {
				tpdm_rdpm_cmb1_out_tn_ag: endpoint {
					remote-endpoint =
					<&tn_ag_in_tpdm_rdpm_cmb1>;
				};
			};
		};
	};

	tpdm_rdpm_cmb2: tpdm@111aa000 {
		compatible = "qcom,coresight-tpdm", "arm,primecell";
		reg = <0x0 0x111aa000 0x0 0x1000>;
		reg-names = "tpdm-base";

		device-name = "tpdm_rdpm_cmb2";

		clocks = <&aoss_qmp>;
		clock-names = "apb_pclk";

		out-ports {
			port {
				tpdm_rdpm_cmb2_out_tn_ag: endpoint {
					remote-endpoint =
					<&tn_ag_in_tpdm_rdpm_cmb2>;
				};
			};
		};
	};

	tpdm_ipcc_cmb2: tpdm@111ad000 {
		compatible = "qcom,coresight-tpdm", "arm,primecell";
		reg = <0x0 0x111ad000 0x0 0x1000>;
		reg-names = "tpdm-base";

		device-name = "tpdm_ipcc_cmb2";

		clocks = <&aoss_qmp>;
		clock-names = "apb_pclk";

		out-ports {
			port {
				tpdm_ipcc_cmb2_out_tn_ag: endpoint {
					remote-endpoint =
					<&tn_ag_in_tpdm_ipcc_cmb2>;
				};
			};
		};
	};

	tpdm_ipcc_cmb4: tpdm@111af000 {
		compatible = "qcom,coresight-tpdm", "arm,primecell";
		reg = <0x0 0x111af000 0x0 0x1000>;
		reg-names = "tpdm-base";

		device-name = "tpdm_ipcc_cmb4";

		clocks = <&aoss_qmp>;
		clock-names = "apb_pclk";

		out-ports {
			port {
				tpdm_ipcc_cmb4_out_tn_ag: endpoint {
					remote-endpoint =
					<&tn_ag_in_tpdm_ipcc_cmb4>;
				};
			};
		};
	};

	tpdm_ipcc_cmb0: tpdm@111ab000 {
		compatible = "qcom,coresight-tpdm", "arm,primecell";
		reg = <0x0 0x111ab000 0x0 0x1000>;
		reg-names = "tpdm-base";

		device-name = "tpdm_ipcc_cmb0";

		clocks = <&aoss_qmp>;
		clock-names = "apb_pclk";

		out-ports {
			port {
				tpdm_ipcc_cmb0_out_tn_ag: endpoint {
					remote-endpoint =
					<&tn_ag_in_tpdm_ipcc_cmb0>;
				};
			};
		};
	};

	tpdm_ipcc_cmb3: tpdm@111ae000 {
		compatible = "qcom,coresight-tpdm", "arm,primecell";
		reg = <0x0 0x111ae000 0x0 0x1000>;
		reg-names = "tpdm-base";

		device-name = "tpdm_ipcc_cmb3";

		clocks = <&aoss_qmp>;
		clock-names = "apb_pclk";

		out-ports {
			port {
				tpdm_ipcc_cmb3_out_tn_ag: endpoint {
					remote-endpoint =
					<&tn_ag_in_tpdm_ipcc_cmb3>;
				};
			};
		};
	};

	tpdm_crm: tpdm@111b2000 {
		compatible = "qcom,coresight-tpdm", "arm,primecell";
		reg = <0x0 0x111b2000 0x0 0x1000>;
		reg-names = "tpdm-base";

		device-name = "tpdm_crm";

		clocks = <&aoss_qmp>;
		clock-names = "apb_pclk";

		out-ports {
			port {
				tpdm_crm_out_tn_ag: endpoint {
					remote-endpoint =
					<&tn_ag_in_tpdm_crm>;
				};
			};
		};
	};

	tpdm_lmh: tpdm@111b1000 {
		compatible = "qcom,coresight-tpdm", "arm,primecell";
		reg = <0x0 0x111b1000 0x0 0x1000>;
		reg-names = "tpdm-base";

		device-name = "tpdm_lmh";

		clocks = <&aoss_qmp>;
		clock-names = "apb_pclk";

		out-ports {
			port {
				tpdm_lmh_out_tn_ag: endpoint {
					remote-endpoint =
					<&tn_ag_in_tpdm_lmh>;
				};
			};
		};
	};

	tpdm_dpm: tpdm@111b0000 {
		compatible = "qcom,coresight-tpdm", "arm,primecell";
		reg = <0x0 0x111b0000 0x0 0x1000>;
		reg-names = "tpdm-base";

		device-name = "tpdm_dpm";

		clocks = <&aoss_qmp>;
		clock-names = "apb_pclk";

		out-ports {
			port {
				tpdm_dpm_out_tn_ag: endpoint {
					remote-endpoint =
					<&tn_ag_in_tpdm_dpm>;
				};
			};
		};
	};

	tn_ag: tn@111b8000 {
		compatible = "arm,primecell";
		arm,primecell-periphid = <0x000f0c00>;
		reg = <0x0 0x111b8000 0x0 0x4200>;
		reg-names = "traceNoc-base";

		device-name = "tracenoc_ag";

		clocks = <&aoss_qmp>;
		clock-names = "apb_pclk";

		in-ports {
			#address-cells = <1>;
			#size-cells = <0>;
			port@8 {
				reg = <8>;
				tn_ag_in_tpdm_pcie_rscc: endpoint {
					remote-endpoint =
					<&tpdm_pcie_rscc_out_tn_ag>;
				};
			};

			port@9 {
				reg = <9>;
				tn_ag_in_funnel_spss: endpoint {
					remote-endpoint =
					<&funnel_spss_out_tn_ag>;
				};
			};


			port@c {
				reg = <12>;
				tn_ag_in_funnel_tmess: endpoint {
					remote-endpoint =
					<&funnel_tmess_out_tn_ag>;
				};
			};

			port@d {
				reg = <13>;
				tn_ag_in_funnel_modem_dl: endpoint {
					remote-endpoint =
					<&funnel_modem_dl_out_tn_ag>;
				};
			};

			port@10 {
				reg = <16>;
				tn_ag_in_funnel_turing: endpoint {
					remote-endpoint =
					<&funnel_turing_out_tn_ag>;
				};
			};

			port@11 {
				reg = <17>;
				tn_ag_in_tpdm_gcc: endpoint {
					remote-endpoint =
					<&tpdm_gcc_out_tn_ag>;
				};
			};

			port@12 {
				reg = <18>;
				tn_ag_in_tpdm_qrng: endpoint {
					remote-endpoint =
					<&tpdm_qrng_out_tn_ag>;
				};
			};

			port@13 {
				reg = <19>;
				tn_ag_in_tpdm_qm: endpoint {
					remote-endpoint =
					<&tpdm_qm_out_tn_ag>;
				};
			};

			port@14 {
				reg = <20>;
				tn_ag_in_tpdm_vsense: endpoint {
					remote-endpoint =
					<&tpdm_vsense_out_tn_ag>;
				};
			};

			port@15 {
				reg = <21>;
				tn_ag_in_tpdm_ipa: endpoint {
					remote-endpoint =
					<&tpdm_ipa_out_tn_ag>;
				};
			};

			port@16 {
				reg = <22>;
				tn_ag_in_tpdm_sdcc5_2: endpoint {
					remote-endpoint =
					<&tpdm_sdcc5_2_out_tn_ag>;
				};
			};

			port@17 {
				reg = <23>;
				tn_ag_in_tpdm_sdcc5_4: endpoint {
					remote-endpoint =
					<&tpdm_sdcc5_4_out_tn_ag>;
				};
			};

			port@18 {
				reg = <24>;
				tn_ag_in_tpdm_ufs: endpoint {
					remote-endpoint =
					<&tpdm_ufs_out_tn_ag>;
				};
			};

			port@19 {
				reg = <25>;
				tn_ag_in_tpdm_dlmm: endpoint {
					remote-endpoint =
					<&tpdm_dlmm_out_tn_ag>;
				};
			};

			port@1a {
				reg = <26>;
				tn_ag_in_tpdm_north_dsb: endpoint {
					remote-endpoint =
					<&tpdm_north_dsb_out_tn_ag>;
				};
			};

			port@1b {
				reg = <27>;
				tn_ag_in_tpdm_south_dsb: endpoint {
					remote-endpoint =
					<&tpdm_south_dsb_out_tn_ag>;
				};
			};

			port@1c {
				reg = <28>;
				tn_ag_in_tpdm_ipcc_cmb1: endpoint {
					remote-endpoint =
					<&tpdm_ipcc_cmb1_out_tn_ag>;
				};
			};

			port@1d {
				reg = <29>;
				tn_ag_in_tpdm_pmu: endpoint {
					remote-endpoint =
					<&tpdm_pmu_out_tn_ag>;
				};
			};

			port@1e {
				reg = <30>;
				tn_ag_in_tpdm_rdpm_cmb0: endpoint {
					remote-endpoint =
					<&tpdm_rdpm_cmb0_out_tn_ag>;
				};
			};

			port@1f {
				reg = <31>;
				tn_ag_in_tpdm_rdpm_cmb1: endpoint {
					remote-endpoint =
					<&tpdm_rdpm_cmb1_out_tn_ag>;
				};
			};

			port@20 {
				reg = <32>;
				tn_ag_in_tpdm_rdpm_cmb2: endpoint {
					remote-endpoint =
					<&tpdm_rdpm_cmb2_out_tn_ag>;
				};
			};

			port@21 {
				reg = <33>;
				tn_ag_in_funnel_apss: endpoint {
					remote-endpoint =
					<&funnel_apss_out_tn_ag>;
				};
			};

			port@22 {
				reg = <34>;
				tn_ag_in_tpdm_ipcc_cmb2: endpoint {
					remote-endpoint =
					<&tpdm_ipcc_cmb2_out_tn_ag>;
				};
			};

			port@23 {
				reg = <35>;
				tn_ag_in_tpdm_ipcc_cmb4: endpoint {
					remote-endpoint =
					<&tpdm_ipcc_cmb4_out_tn_ag>;
				};
			};

			port@24 {
				reg = <36>;
				tn_ag_in_tpdm_ipcc_cmb0: endpoint {
					remote-endpoint =
					<&tpdm_ipcc_cmb0_out_tn_ag>;
				};
			};

			port@25 {
				reg = <37>;
				tn_ag_in_tpdm_ipcc_cmb3: endpoint {
					remote-endpoint =
					<&tpdm_ipcc_cmb3_out_tn_ag>;
				};
			};

			port@29 {
				reg = <41>;
				tn_ag_in_tpdm_crm: endpoint {
					remote-endpoint =
					<&tpdm_crm_out_tn_ag>;
				};
			};

			port@2a {
				reg = <42>;
				tn_ag_in_tpdm_lmh: endpoint {
					remote-endpoint =
					<&tpdm_lmh_out_tn_ag>;
				};
			};

			port@2b {
				reg = <43>;
				tn_ag_in_tpdm_dpm: endpoint {
					remote-endpoint =
					<&tpdm_dpm_out_tn_ag>;
				};
			};

			port@37 {
				reg = <55>;
				tn_ag_in_tn_lpass: endpoint {
					remote-endpoint =
					<&tn_lpass_out_tn_ag>;
				};
			};

			port@39 {
				reg = <57>;
				tn_ag_in_tn_soccp: endpoint {
					remote-endpoint =
					<&tn_soccp_out_tn_ag>;
				};
			};

			port@40 {
				reg = <64>;
				tn_ag_in_tn_video: endpoint {
					remote-endpoint =
					<&tn_video_out_tn_ag>;
				};
			};

			port@48 {
				reg = <72>;
				tn_ag_in_tn_eva: endpoint {
					remote-endpoint =
					<&tn_eva_out_tn_ag>;
				};
			};

			port@50 {
				reg = <80>;
				tn_ag_in_tn_mdss: endpoint {
					remote-endpoint =
					<&tn_mdss_out_tn_ag>;
				};
			};

			port@58 {
				reg = <88>;
				tn_ag_in_tn_gpu: endpoint {
					remote-endpoint =
					<&tn_gpu_out_tn_ag>;
				};
			};

			port@60 {
				reg = <96>;
				tn_ag_in_tn_ddr: endpoint {
					remote-endpoint =
					<&tn_ddr_out_tn_ag>;
				};
			};
		};

		out-ports {
			port {
				tn_ag_out_funnel_in0: endpoint {
					remote-endpoint =
					<&funnel_in0_in_tn_ag>;
				};
			};
		};
	};

	stm: stm@10002000 {
		compatible = "arm,coresight-stm", "arm,primecell";
		reg = <0x0 0x10002000 0x0 0x1000>,
			<0x0 0x16280000 0x0 0x180000>;
		reg-names = "stm-base", "stm-stimulus-base";
		atid = <16>;

		clocks = <&aoss_qmp>;
		clock-names = "apb_pclk";

		out-ports {
			port {
				stm_out_funnel_in0: endpoint {
					remote-endpoint =
					<&funnel_in0_in_stm>;
				};
			};
		};
	};

	tpdm_dcc: tpdm@10003000 {
		compatible = "qcom,coresight-tpdm", "arm,primecell";
		reg = <0x0 0x10003000 0x0 0x1000>;
		reg-names = "tpdm-base";
		qcom,cmb-element-bits = <32>;

		device-name = "tpdm_dcc";

		qcom,hw-enable-check;
		clocks = <&aoss_qmp>;
		clock-names = "apb_pclk";

		out-ports {
			port {
				tpdm_dcc_out_tpda_qdss: endpoint {
					remote-endpoint =
					<&tpda_qdss_in_tpdm_dcc>;
				};
			};
		};
	};

	tpdm_spdm: tpdm@1000f000 {
		compatible = "qcom,coresight-tpdm", "arm,primecell";
		reg = <0x0 0x1000f000 0x0 0x1000>;
		qcom,cmb-element-bits = <32>;
		reg-names = "tpdm-base";

		device-name = "tpdm_spdm";

		clocks = <&aoss_qmp>;
		clock-names = "apb_pclk";

		out-ports {
			port {
				tpdm_spdm_out_tpda_qdss: endpoint {
					remote-endpoint =
					<&tpda_qdss_in_tpdm_spdm>;
				};
			};
		};
	};

	tpda_qdss: tpda@10004000 {
		compatible = "qcom,coresight-tpda", "arm,primecell";
		reg = <0x0 0x10004000 0x0 0x1000>;
		reg-names = "tpda-base";

		device-name = "tpda_qdss";

		clocks = <&aoss_qmp>;
		clock-names = "apb_pclk";

		in-ports {
			#address-cells = <1>;
			#size-cells = <0>;

			port@0 {
				reg = <0>;
				tpda_qdss_in_tpdm_dcc: endpoint {
					remote-endpoint =
					<&tpdm_dcc_out_tpda_qdss>;
				};
			};

			port@1 {
				reg = <1>;
				tpda_qdss_in_tpdm_spdm: endpoint {
					remote-endpoint =
					<&tpdm_spdm_out_tpda_qdss>;
				};
			};

		};

		out-ports {
			port {
				tpda_qdss_out_funnel_in0: endpoint {
					remote-endpoint =
					<&funnel_in0_in_tpda_qdss>;
				};
			};
		};
	};

	funnel_in0: funnel@10041000 {
		compatible = "arm,coresight-dynamic-funnel", "arm,primecell";
		reg = <0x0 0x10041000 0x0 0x1000>;
		reg-names = "funnel-base";

		device-name = "funnel_in0";

		clocks = <&aoss_qmp>;
		clock-names = "apb_pclk";

		in-ports {
			#address-cells = <1>;
			#size-cells = <0>;

			port@0 {
				reg = <0>;
				funnel_in0_in_tn_ag: endpoint {
					remote-endpoint =
					<&tn_ag_out_funnel_in0>;
				};
			};

			port@6 {
				reg = <6>;
				funnel_in0_in_tpda_qdss: endpoint {
					remote-endpoint =
					<&tpda_qdss_out_funnel_in0>;
				};
			};

			port@7 {
				reg = <7>;
				funnel_in0_in_stm: endpoint {
					remote-endpoint =
					<&stm_out_funnel_in0>;
				};
			};
		};

		out-ports {
			port {
				funnel_in0_out_funnel_aoss: endpoint {
					remote-endpoint =
					<&funnel_aoss_in_funnel_in0>;
				};
			};
		};
	};

	tpdm_swao_prio0: tpdm@11309000 {
		compatible = "qcom,coresight-tpdm", "arm,primecell";
		reg = <0x0 0x11309000 0x0 0x1000>;
		reg-names = "tpdm-base";
		qcom,cmb-element-bits = <64>;

		device-name = "tpdm_swao_prio_0";

		clocks = <&aoss_qmp>;
		clock-names = "apb_pclk";

		out-ports {
			port {
				tpdm_swao_prio0_out_tpda_aoss: endpoint {
					remote-endpoint =
					<&tpda_aoss_in_tpdm_swao_prio0>;
				};
			};
		};
	};

	tpdm_swao_prio1: tpdm@1130a000 {
		compatible = "qcom,coresight-tpdm", "arm,primecell";
		reg = <0x0 0x1130a000 0x0 0x1000>;
		reg-names = "tpdm-base";
		qcom,cmb-element-bits = <64>;

		device-name = "tpdm_swao_prio_1";

		clocks = <&aoss_qmp>;
		clock-names = "apb_pclk";

		out-ports {
			port {
				tpdm_swao_prio1_out_tpda_aoss: endpoint {
					remote-endpoint =
					<&tpda_aoss_in_tpdm_swao_prio1>;
				};
			};
		};
	};

	tpdm_swao_prio2: tpdm@1130b000 {
		compatible = "qcom,coresight-tpdm", "arm,primecell";
		reg = <0x0 0x1130b000 0x0 0x1000>;
		reg-names = "tpdm-base";
		qcom,cmb-element-bits = <64>;

		device-name = "tpdm_swao_prio_2";

		clocks = <&aoss_qmp>;
		clock-names = "apb_pclk";

		out-ports {
			port {
				tpdm_swao_prio2_out_tpda_aoss: endpoint {
					remote-endpoint =
					<&tpda_aoss_in_tpdm_swao_prio2>;
				};
			};
		};
	};

	tpdm_swao_prio3: tpdm@1130c000 {
		compatible = "qcom,coresight-tpdm", "arm,primecell";
		reg = <0x0 0x1130c000 0x0 0x1000>;
		reg-names = "tpdm-base";
		qcom,cmb-element-bits = <64>;

		device-name = "tpdm_swao_prio_3";

		clocks = <&aoss_qmp>;
		clock-names = "apb_pclk";

		out-ports {
			port {
				tpdm_swao_prio3_out_tpda_aoss: endpoint {
					remote-endpoint =
					<&tpda_aoss_in_tpdm_swao_prio3>;
				};
			};
		};
	};

	tpdm_swao_prio4: tpdm@11303000 {
		compatible = "qcom,coresight-tpdm", "arm,primecell";
		reg = <0x0 0x11303000 0x0 0x1000>;
		reg-names = "tpdm-base";
		qcom,cmb-element-bits = <64>;

		device-name = "tpdm_swao_prio_4";

		clocks = <&aoss_qmp>;
		clock-names = "apb_pclk";

		out-ports {
			port {
				tpdm_swao_prio4_out_tpda_aoss: endpoint {
					remote-endpoint =
					<&tpda_aoss_in_tpdm_swao_prio4>;
				};
			};
		};
	};

	tpdm_swao: tpdm@1130d000 {
		compatible = "qcom,coresight-tpdm", "arm,primecell";
		reg = <0x0 0x1130d000 0x0 0x1000>;
		reg-names = "tpdm-base";
		qcom,dsb-element-bits = <32>;

		device-name = "tpdm_swao_1";

		clocks = <&aoss_qmp>;
		clock-names = "apb_pclk";

		out-ports {
			port {
				tpdm_swao_out_tpda_aoss: endpoint {
					remote-endpoint =
					<&tpda_aoss_in_tpdm_swao>;
				};
			};
		};
	};

	tpda_aoss: tpda@11308000 {
		compatible = "qcom,coresight-tpda", "arm,primecell";
		reg = <0x0 0x11308000 0x0 0x1000>;
		reg-names = "tpda-base";

		device-name = "tpda_aoss";

		clocks = <&aoss_qmp>;
		clock-names = "apb_pclk";

		in-ports {
			#address-cells = <1>;
			#size-cells = <0>;

			port@0 {
				reg = <0>;
				tpda_aoss_in_tpdm_swao_prio0: endpoint {
					remote-endpoint =
					<&tpdm_swao_prio0_out_tpda_aoss>;
				};
			};

			port@1 {
				reg = <1>;
				tpda_aoss_in_tpdm_swao_prio1: endpoint {
					remote-endpoint =
					<&tpdm_swao_prio1_out_tpda_aoss>;
				};
			};

			port@2 {
				reg = <2>;
				tpda_aoss_in_tpdm_swao_prio2: endpoint {
					remote-endpoint =
					<&tpdm_swao_prio2_out_tpda_aoss>;
				};
			};

			port@3 {
				reg = <3>;
				tpda_aoss_in_tpdm_swao_prio3: endpoint {
					remote-endpoint =
					<&tpdm_swao_prio3_out_tpda_aoss>;
				};
			};

			port@4 {
				reg = <4>;
				tpda_aoss_in_tpdm_swao_prio4: endpoint {
					remote-endpoint =
					<&tpdm_swao_prio4_out_tpda_aoss>;
				};
			};

			port@5 {
				reg = <5>;
				tpda_aoss_in_tpdm_swao: endpoint {
					remote-endpoint =
					<&tpdm_swao_out_tpda_aoss>;
				};
			};
		};

		out-ports {
			port {
				tpda_aoss_out_funnel_aoss: endpoint {
					remote-endpoint =
					<&funnel_aoss_in_tpda_aoss>;
				};
			};
		};
	};

	funnel_aoss: funnel@11304000 {
		compatible = "arm,coresight-dynamic-funnel", "arm,primecell";
		reg = <0x0 0x11304000 0x0 0x1000>;
		reg-names = "funnel-base";

		device-name = "funnel_aoss";

		clocks = <&aoss_qmp>;
		clock-names = "apb_pclk";

		in-ports {
			#address-cells = <1>;
			#size-cells = <0>;

			port@5 {
				reg = <5>;
				funnel_aoss_in_tpda_aoss: endpoint {
					remote-endpoint =
					<&tpda_aoss_out_funnel_aoss>;
				};
			};

			port@6 {
				reg = <6>;
				funnel_aoss_in_funnel_in0: endpoint {
					remote-endpoint =
					<&funnel_in0_out_funnel_aoss>;
				};
			};

		};

		out-ports {
			port {
				funnel_aoss_out_tmc_etf: endpoint {
					remote-endpoint =
					<&tmc_etf_in_funnel_aoss>;
				};
			};
		};
	};

	tmc_etf: tmc@11305000 {
		compatible = "arm,coresight-tmc", "arm,primecell";
		reg = <0x0 0x11305000 0x0 0x1000>;
		reg-names = "tmc-base";

		clocks = <&aoss_qmp>;
		clock-names = "apb_pclk";

		in-ports {
			port {
				tmc_etf_in_funnel_aoss: endpoint {
					remote-endpoint =
					<&funnel_aoss_out_tmc_etf>;
				};
			};
		};

		out-ports {
			port {
				tmc_etf_out_replicator_swao: endpoint {
					remote-endpoint =
					<&replicator_swao_in_tmc_etf>;
				};
			};
		};
	};

	replicator_swao: replicator@11306000 {
		compatible = "arm,primecell";
		arm,primecell-periphid = <0x000bb909>;
		reg = <0x0 0x11306000 0x0 0x1000>;
		reg-names = "replicator-base";

		device-name = "replicator_swao";

		qcom,replicator-loses-context;
		clocks = <&aoss_qmp>;
		clock-names = "apb_pclk";

		in-ports {
			port {
				replicator_swao_in_tmc_etf: endpoint {
					remote-endpoint =
					<&tmc_etf_out_replicator_swao>;
				};
			};
		};

		out-ports {
			#address-cells = <1>;
			#size-cells = <0>;

			port@0 {
				replicator_swao_out_replicator_qdss: endpoint {
					remote-endpoint =
					<&replicator_qdss_in_replicator_swao>;
				};
			};

			port@1 {
				reg = <1>;
				replicator_swao_out_eud: endpoint {
					remote-endpoint =
					  <&eud_in_replicator_swao>;
				};
			};
		};
	};

	dummy_eud: dummy-eud {
		compatible = "arm,coresight-dummy-sink";

		device-name = "eud";

		in-ports {
			port {
				eud_in_replicator_swao: endpoint {
					remote-endpoint =
						<&replicator_swao_out_eud>;
				};
			};
		};
	};

	replicator_qdss: replicator@10046000 {
		compatible = "arm,primecell";
		arm,primecell-periphid = <0x000bb909>;
		reg = <0x0 0x10046000 0x0 0x1000>;
		reg-names = "replicator-base";

		device-name = "replicator_qdss";

		clocks = <&aoss_qmp>;
		clock-names = "apb_pclk";

		in-ports {
			port {
				replicator_qdss_in_replicator_swao: endpoint {
					remote-endpoint =
					<&replicator_swao_out_replicator_qdss>;
				};
			};
		};

		out-ports {
			#address-cells = <1>;
			#size-cells = <0>;

			port@0 {
				replicator_qdss_out_replicator_etr: endpoint {
					remote-endpoint =
					<&replicator_etr_in_replicator_qdss>;
				};
			};
		};
	};

	replicator_etr: replicator@1004e000 {
		compatible = "arm,primecell";
		arm,primecell-periphid = <0x000bb909>;
		reg = <0x0 0x1004e000 0x0 0x1000>;
		reg-names = "replicator-base";

		device-name = "replicator_etr";

		clocks = <&aoss_qmp>;
		clock-names = "apb_pclk";

		in-ports {
			port {
				replicator_etr_in_replicator_qdss: endpoint {
					remote-endpoint =
					<&replicator_qdss_out_replicator_etr>;
				};
			};
		};

		out-ports {
			#address-cells = <1>;
			#size-cells = <0>;

			port@0 {
				reg = <0>;
				replicator_etr_out_tmc_etr: endpoint {
					remote-endpoint =
					<&tmc_etr_in_replicator_etr>;
				};
			};
		};
	};

	tmc_etr: tmc@10048000 {
		compatible = "arm,primecell";
		arm,primecell-periphid = <0x000bb961>;
		reg = <0x0 0x10048000 0x0 0x1000>;
		reg-names = "tmc-base";

		device-name = "etr0";

		qcom,iommu-dma = "bypass";
		iommus = <&apps_smmu 0x04e0 0x0>;
		dma-coherent;
		arm,scatter-gather;

		//usb_bamless_support;
		qcom,sw-usb;
		coresight-csr = <&csr>;
		csr-atid-offset = <0xf8>;
		csr-irqctrl-offset = <0x6c>;
		byte-cntr-name = "byte-cntr";
		byte-cntr-class-name = "coresight-tmc-etr-stream";
		interrupts = <GIC_SPI 738 IRQ_TYPE_EDGE_RISING>;
		interrupt-names = "byte-cntr-irq";

		clocks = <&aoss_qmp>;
		clock-names = "apb_pclk";

		in-ports {
			port {
				tmc_etr_in_replicator_etr: endpoint {
					remote-endpoint =
					<&replicator_etr_out_tmc_etr>;
				};
			};
		};
	};

	cti@10010000 {
		compatible = "arm,coresight-cti", "arm,primecell";
		reg = <0x0 0x10010000 0x0 0x1000>;

		arm,primecell-periphid = <0x000bb922>;
		device-name = "cti_qdss";

		qcom,extended_cti;
		clocks = <&aoss_qmp>;
		clock-names = "apb_pclk";

		qcom,cti-gpio-trigout = <16>;
		pinctrl-names = "cti-trigout-pctrl";
//		pinctrl-0 = <&trigout_a>;
	};

	cti@11003000 {
		compatible = "arm,coresight-cti", "arm,primecell";
		reg = <0x0 0x11003000 0x0 0x1000>;

		arm,primecell-periphid = <0x000bb922>;
		device-name = "cti_mss";

		qcom,extended_cti;
		clocks = <&aoss_qmp>;
		clock-names = "apb_pclk";
	};

	cti@1100b000 {
		compatible = "arm,coresight-cti", "arm,primecell";
		reg = <0x0 0x1100b000 0x0 0x1000>;

		arm,primecell-periphid = <0x000bb922>;
		device-name = "cti_mss_qdsp6";

		clocks = <&aoss_qmp>;
		clock-names = "apb_pclk";
	};

	cti@11013000 {
		compatible = "arm,coresight-cti", "arm,primecell";
		reg = <0x0 0x11013000 0x0 0x1000>;

		arm,primecell-periphid = <0x000bb922>;
		device-name = "cti_mss_vdsp6";

		clocks = <&aoss_qmp>;
		clock-names = "apb_pclk";
		status = "disabled";
	};

	cti@11035000 {
		compatible = "arm,coresight-cti", "arm,primecell";
		reg = <0x0 0x11035000 0x0 0x1000>;

		arm,primecell-periphid = <0x000bb922>;
		device-name = "cti_venus";

		clocks = <&aoss_qmp>;
		clock-names = "apb_pclk";
		qcom,extended_cti;
	};

	cti@11104000 {
		compatible = "arm,coresight-cti", "arm,primecell";
		reg = <0x0 0x11104000 0x0 0x1000>;

		arm,primecell-periphid = <0x000bb922>;
		device-name = "cti_a6x_tracenoc";

		qcom,extended_cti;
		clocks = <&aoss_qmp>;
		clock-names = "apb_pclk";
		status = "disabled";
	};

	cti@11161000 {
		compatible = "arm,coresight-cti", "arm,primecell";
		reg = <0x0 0x11161000 0x0 0x1000>;

		arm,primecell-periphid = <0x000bb922>;
		device-name = "cti_a6x_isdb";

		clocks = <&aoss_qmp>;
		clock-names = "apb_pclk";
		status = "disabled";
	};

	cti@11162000 {
		compatible = "arm,coresight-cti", "arm,primecell";
		reg = <0x0 0x11162000 0x0 0x1000>;

		arm,primecell-periphid = <0x000bb922>;
		device-name = "cti_a6x_gpmu";

		clocks = <&aoss_qmp>;
		clock-names = "apb_pclk";
		status = "disabled";
	};

	cti@11187000 {
		compatible = "arm,coresight-cti", "arm,primecell";
		reg = <0x0 0x11187000 0x0 0x1000>;

		arm,primecell-periphid = <0x000bb922>;
		device-name = "cti_turing";

		qcom,extended_cti;
		clocks = <&aoss_qmp>;
		clock-names = "apb_pclk";
	};

	cti@11193000 {
		compatible = "arm,coresight-cti", "arm,primecell";
		reg = <0x0 0x11193000 0x0 0x1000>;

		arm,primecell-periphid = <0x000bb922>;
		device-name = "cti_turing_qdsp";

		clocks = <&aoss_qmp>;
		clock-names = "apb_pclk";
	};

	cti@111a0000 {
		compatible = "arm,coresight-cti", "arm,primecell";
		reg = <0x0 0x111a0000 0x0 0x1000>;

		arm,primecell-periphid = <0x000bb922>;
		device-name = "cti_trace_noc_cti0";

		clocks = <&aoss_qmp>;
		clock-names = "apb_pclk";
		qcom,extended_cti;
	};

	cti@111a1000 {
		compatible = "arm,coresight-cti", "arm,primecell";
		reg = <0x0 0x111a1000 0x0 0x1000>;

		arm,primecell-periphid = <0x000bb922>;
		device-name = "cti_trace_noc_cti2";

		clocks = <&aoss_qmp>;
		clock-names = "apb_pclk";
		qcom,extended_cti;
	};

	cti@111a2000 {
		compatible = "arm,coresight-cti", "arm,primecell";
		reg = <0x0 0x111a2000 0x0 0x1000>;

		arm,primecell-periphid = <0x000bb922>;
		device-name = "cti_trace_noc_cti0_mm";

		clocks = <&aoss_qmp>;
		clock-names = "apb_pclk";
		qcom,extended_cti;
	};

	cti@111c5000 {
		compatible = "arm,coresight-cti", "arm,primecell";
		reg = <0x0 0x111c5000 0x0 0x1000>;

		arm,primecell-periphid = <0x000bb922>;
		device-name = "cti_eva";

		clocks = <&aoss_qmp>;
		clock-names = "apb_pclk";
		qcom,extended_cti;
	};

	cti@11207000 {
		compatible = "arm,coresight-cti", "arm,primecell";
		reg = <0x0 0x11207000 0x0 0x1000>;

		arm,primecell-periphid = <0x000bb922>;
		device-name = "cti_camera";

		qcom,extended_cti;
		clocks = <&aoss_qmp>;
		clock-names = "apb_pclk";
		status = "disabled";
	};

	swao_cti: cti@11300000 {
		compatible = "arm,coresight-cti", "arm,primecell";
		reg = <0x0 0x11300000 0x0 0x1000>;

		arm,primecell-periphid = <0x000bb922>;
		device-name = "cti_swao";
		qcom,extended_cti;
		clocks = <&aoss_qmp>;
		clock-names = "apb_pclk";
	};

	cti@11321000 {
		compatible = "arm,coresight-cti", "arm,primecell";
		reg = <0x0 0x11321000 0x0 0x1000>;

		arm,primecell-periphid = <0x000bb922>;
		device-name = "cti_aoss";

		clocks = <&aoss_qmp>;
		clock-names = "apb_pclk";
		status = "disabled";
	};

	cti@11335000 {
		compatible = "arm,coresight-cti", "arm,primecell";
		reg = <0x0 0x11335000 0x0 0x1000>;

		arm,primecell-periphid = <0x000bb922>;
		device-name = "cti_ddr_lpi";

		qcom,extended_cti;
		clocks = <&aoss_qmp>;
		clock-names = "apb_pclk";
		status = "disabled";
	};

	cti@11341000 {
		compatible = "arm,coresight-cti", "arm,primecell";
		reg = <0x0 0x11341000 0x0 0x1000>;

		arm,primecell-periphid = <0x000bb922>;
		device-name = "cti_lpass_lpi_cti_1";

		clocks = <&aoss_qmp>;
		clock-names = "apb_pclk";
		status = "disabled";
	};

	cti@11342000 {
		compatible = "arm,coresight-cti", "arm,primecell";
		reg = <0x0 0x11342000 0x0 0x1000>;

		arm,primecell-periphid = <0x000bb922>;
		device-name = "cti_lpass_lpi";

		clocks = <&aoss_qmp>;
		clock-names = "apb_pclk";
		status = "disabled";
	};

	cti@1134b000 {
		compatible = "arm,coresight-cti", "arm,primecell";
		reg = <0x0 0x1134b000 0x0 0x1000>;

		arm,primecell-periphid = <0x000bb922>;
		device-name = "cti_lpass_lpi_qdsp";

		clocks = <&aoss_qmp>;
		clock-names = "apb_pclk";
		status = "disabled";
	};

	cti@11354000 {
		compatible = "arm,coresight-cti", "arm,primecell";
		reg = <0x0 0x11354000 0x0 0x1000>;

		arm,primecell-periphid = <0x000bb922>;
		device-name = "cti_lpass_lpi_cti_3";

		clocks = <&aoss_qmp>;
		clock-names = "apb_pclk";
		status = "disabled";
	};

	cti@11385000 {
		compatible = "arm,coresight-cti", "arm,primecell";
		reg = <0x0 0x11385000 0x0 0x1000>;

		arm,primecell-periphid = <0x000bb922>;
		device-name = "cti_lpass";

		qcom,extended_cti;
		clocks = <&aoss_qmp>;
		clock-names = "apb_pclk";
	};

	cti@113a5000 {
		compatible = "arm,coresight-cti", "arm,primecell";
		reg = <0x0 0x113a5000 0x0 0x1000>;

		arm,primecell-periphid = <0x000bb922>;
		device-name = "cti_soccp";

		clocks = <&aoss_qmp>;
		clock-names = "apb_pclk";
		qcom,extended_cti;
	};

	cti@11466000 {
		compatible = "arm,coresight-cti", "arm,primecell";
		reg = <0x0 0x11466000 0x0 0x1000>;

		arm,primecell-periphid = <0x000bb922>;
		device-name = "cti_mdss";

		qcom,extended_cti;
		clocks = <&aoss_qmp>;
		clock-names = "apb_pclk";
	};

	cti@114c4000 {
		compatible = "arm,coresight-cti", "arm,primecell";
		reg = <0x0 0x114c4000 0x0 0x1000>;

		arm,primecell-periphid = <0x000bb922>;
		device-name = "cti_tmess_dragonlink_cti0";

		clocks = <&aoss_qmp>;
		clock-names = "apb_pclk";
		qcom,extended_cti;
		status = "disabled";
	};

	cti@114c5000 {
		compatible = "arm,coresight-cti", "arm,primecell";
		reg = <0x0 0x114c5000 0x0 0x1000>;

		arm,primecell-periphid = <0x000bb922>;
		device-name = "cti_tmess_dragonlink_cti1";

		clocks = <&aoss_qmp>;
		clock-names = "apb_pclk";
		qcom,extended_cti;
		status = "disabled";
	};

	cti@114d1000 {
		compatible = "arm,coresight-cti", "arm,primecell";
		reg = <0x0 0x114d1000 0x0 0x1000>;

		arm,primecell-periphid = <0x000bb922>;
		device-name = "cti_tmess_rvss";

		clocks = <&aoss_qmp>;
		clock-names = "apb_pclk";
		status = "disabled";
	};

	cti@114e1000 {
		compatible = "arm,coresight-cti", "arm,primecell";
		reg = <0x0 0x114e1000 0x0 0x1000>;

		arm,primecell-periphid = <0x000bb922>;
		device-name = "cti_tmess_rvss_seqr";

		clocks = <&aoss_qmp>;
		clock-names = "apb_pclk";
		status = "disabled";
	};

	cti@1150a000 {
		compatible = "arm,coresight-cti", "arm,primecell";
		reg = <0x0 0x1150a000 0x0 0x1000>;

		arm,primecell-periphid = <0x000bb922>;
		device-name = "cti_ddr_center";

		qcom,extended_cti;
		clocks = <&aoss_qmp>;
		clock-names = "apb_pclk";
	};

	cti@1150c000 {
		compatible = "arm,coresight-cti", "arm,primecell";
		reg = <0x0 0x1150c000 0x0 0x1000>;

		arm,primecell-periphid = <0x000bb922>;
		device-name = "cti_ddr_chhm02";

		qcom,extended_cti;
		clocks = <&aoss_qmp>;
		clock-names = "apb_pclk";
	};

	cti@1150d000 {
		compatible = "arm,coresight-cti", "arm,primecell";
		reg = <0x0 0x1150d000 0x0 0x1000>;

		arm,primecell-periphid = <0x000bb922>;
		device-name = "cti_ddr_chhm13";

		qcom,extended_cti;
		clocks = <&aoss_qmp>;
		clock-names = "apb_pclk";
	};

	cti@11561000 {
		compatible = "arm,coresight-cti", "arm,primecell";
		reg = <0x0 0x11561000 0x0 0x1000>;

		arm,primecell-periphid = <0x000bb922>;
		device-name = "cti_ddr_shrm";

		clocks = <&aoss_qmp>;
		clock-names = "apb_pclk";
		status = "disabled";
	};

	cti@120c0000 {
		compatible = "arm,coresight-cti", "arm,primecell";
		reg = <0x0 0x120c0000 0x0 0x1000>;

		arm,primecell-periphid = <0x000bb922>;
		device-name = "cti_apss_cti";

		qcom,extended_cti;
		clocks = <&aoss_qmp>,
			<&rpmhcc RPMH_CXO_CLK>;
		clock-names = "apb_pclk",
				"dynamic_clk";
	};

	cti@12195000 {
		compatible = "arm,coresight-cti", "arm,primecell";
		reg = <0x0 0x1218a000 0x0 0x1000>;

		arm,primecell-periphid = <0x000bb922>;
		device-name = "cti_apss_dl";

		qcom,extended_cti;
		clocks = <&aoss_qmp>,
			<&rpmhcc RPMH_CXO_CLK>;
		clock-names = "apb_pclk",
				"dynamic_clk";
	};
};

